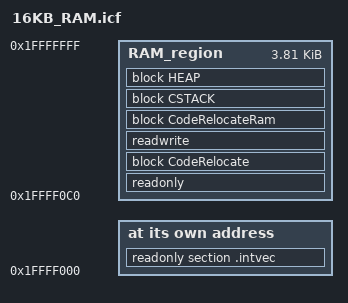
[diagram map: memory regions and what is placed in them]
/*###ICF### Section handled by ICF editor, don't touch! ****/
/*-Editor annotation file-*/
/* IcfEditorFile="$TOOLKIT_DIR$\config\ide\IcfEditor\cortex_v1_0.xml" */
/*-Specials-*/
define symbol __ICFEDIT_intvec_start__ = 0x1FFFF000;
/*-Memory Regions-*/
define symbol __ICFEDIT_region_ROM_start__ 	= 0x00000000;
define symbol __ICFEDIT_region_ROM_end__    = 0x00000000;
define symbol __ICFEDIT_region_RAM_start__  = 0x1FFFF0C0;
define symbol __ICFEDIT_region_RAM_end__    = 0x1FFFFFFF;
/*-Sizes-*/
define symbol __ICFEDIT_size_cstack__   = 0x400;
define symbol __ICFEDIT_size_heap__     = 0x400;
/**** End of ICF editor section. ###ICF###*/

define symbol __region_RAM2_start__   = 0x20000000;
define symbol __region_RAM2_end__     = 0x20002FFF;

define exported symbol __VECTOR_TABLE = __ICFEDIT_intvec_start__;
define exported symbol __VECTOR_RAM   = __ICFEDIT_intvec_start__;

define memory mem with size = 4G;
define region RAM_region   = mem:[from __ICFEDIT_region_RAM_start__  to __ICFEDIT_region_RAM_end__] | [from __region_RAM2_start__   to __region_RAM2_end__];

define block CSTACK    with alignment = 8, size = __ICFEDIT_size_cstack__   { };
define block HEAP      with alignment = 8, size = __ICFEDIT_size_heap__     { };

initialize manually { readwrite };
initialize manually { section .data};
initialize manually { section .textrw };
do not initialize  { section .noinit };

define block CodeRelocate { section .textrw_init };
define block CodeRelocateRam { section .textrw };

place at address mem:__ICFEDIT_intvec_start__ { readonly section .intvec };

place in RAM_region   { readonly, block CodeRelocate};

place in RAM_region   { readwrite, block CodeRelocateRam,
                        block CSTACK, block HEAP };
